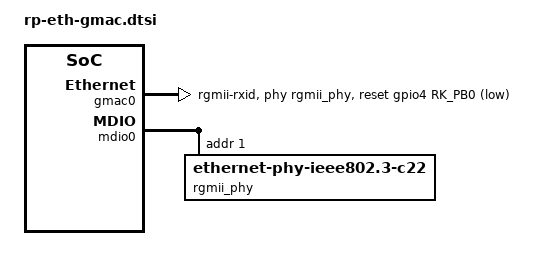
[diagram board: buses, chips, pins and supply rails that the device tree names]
&gmac0 {
	/* Use rgmii-rxid mode to disable rx delay inside Soc */
	phy-mode = "rgmii-rxid";
	clock_in_out = "input";

	snps,reset-gpio = <&gpio4 RK_PB0 GPIO_ACTIVE_LOW>;
	snps,reset-active-low;
	/* Reset time is 20ms, 100ms for rtl8211f */
	snps,reset-delays-us = <0 10000 100000>;
	
	tx_delay = <0x1c>;
	/*rx_delay = <0x3f>;*/

	pinctrl-names = "default";
	pinctrl-0 = <&rgmiim0_miim
		&rgmiim0_tx_bus2
		&rgmiim0_rx_bus2
		&rgmiim0_rgmii_clk
		&rgmiim0_rgmii_bus
		&rgmiim0_clk
		&ethm0_pins>;
	phy-handle = <&rgmii_phy>;
	status = "okay";
};

&mdio0 {
	rgmii_phy: phy@1 {
		compatible = "ethernet-phy-ieee802.3-c22";
		reg = <0x1>;
		clocks = <&cru CLK_GMAC_ETH_OUT2IO>;
		assigned-clocks = <&cru CLK_GMAC_ETH_OUT2IO>;
		assigned-clock-rates = <25000000>;
	};
};
